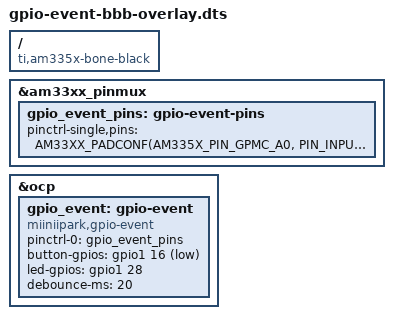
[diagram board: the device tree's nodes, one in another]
/dts-v1/;
/plugin/;

#include <dt-bindings/gpio/gpio.h>
#include <dt-bindings/pinctrl/am33xx.h>

/ {
	compatible = "ti,am335x-bone-black", "ti,am335x-bone", "ti,am33xx";
};

&am33xx_pinmux {
	gpio_event_pins: gpio-event-pins {
		pinctrl-single,pins = <
			/* P9_15: gpio1_16, GPIO48, button input */
			AM33XX_PADCONF(AM335X_PIN_GPMC_A0, PIN_INPUT_PULLUP, MUX_MODE7)

			/* P9_12: gpio1_28, GPIO60, LED output */
			AM33XX_PADCONF(AM335X_PIN_GPMC_BEN1, PIN_OUTPUT, MUX_MODE7)
		>;
	};
};

&ocp {
	gpio_event: gpio-event {
		compatible = "miiniipark,gpio-event";
		status = "okay";

		pinctrl-names = "default";
		pinctrl-0 = <&gpio_event_pins>;

		button-gpios = <&gpio1 16 GPIO_ACTIVE_LOW>;
		led-gpios = <&gpio1 28 GPIO_ACTIVE_HIGH>;

		debounce-ms = <20>;
	};
};
